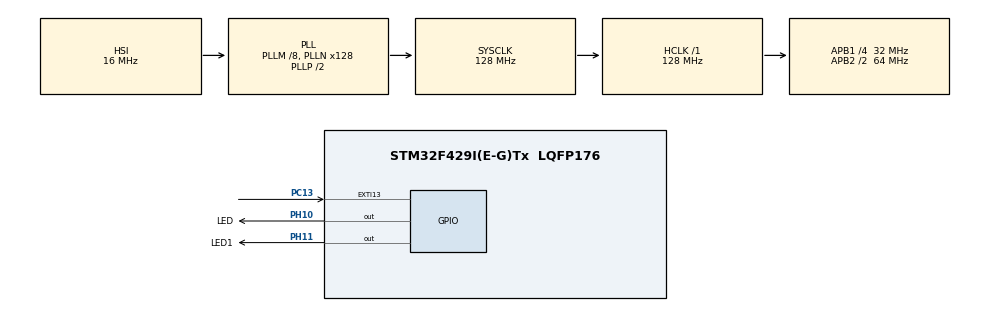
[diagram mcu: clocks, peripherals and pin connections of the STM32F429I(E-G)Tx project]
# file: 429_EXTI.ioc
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Mcu.Family=STM32F4
Mcu.Name=STM32F429I(E-G)Tx
Mcu.Package=LQFP176
NVIC.EXTI15_10_IRQn=true\:1\:0\:true\:false\:true\:true\:true
NVIC.PriorityGroup=NVIC_PRIORITYGROUP_4
PA13.Mode=Serial_Wire
PA13.Signal=SYS_JTMS-SWDIO
PA14.Mode=Serial_Wire
PA14.Signal=SYS_JTCK-SWCLK
PC13.GPIO_ModeDefaultEXTI=GPIO_MODE_IT_RISING_FALLING
PC13.GPIO_PuPd=GPIO_PULLUP
PC13.Signal=GPXTI13
PC14/OSC32_IN.Mode=LSE-External-Oscillator
PC14/OSC32_IN.Signal=RCC_OSC32_IN
PC15/OSC32_OUT.Mode=LSE-External-Oscillator
PC15/OSC32_OUT.Signal=RCC_OSC32_OUT
PH0/OSC_IN.Mode=HSE-External-Oscillator
PH0/OSC_IN.Signal=RCC_OSC_IN
PH1/OSC_OUT.Mode=HSE-External-Oscillator
PH1/OSC_OUT.Signal=RCC_OSC_OUT
PH10.GPIO_Label=LED
PH10.GPIO_PuPd=GPIO_NOPULL
PH10.PinState=GPIO_PIN_SET
PH10.Signal=GPIO_Output
PH11.GPIO_Label=LED1
PH11.GPIO_PuPd=GPIO_PULLUP
PH11.PinState=GPIO_PIN_SET
PH11.Signal=GPIO_Output
ProjectManager.HeapSize=0x200
ProjectManager.StackSize=0x400
ProjectManager.TargetToolchain=MDK-ARM V5
RCC.48MHZClocksFreq_Value=64000000
RCC.AHBFreq_Value=128000000
RCC.APB1CLKDivider=RCC_HCLK_DIV4
RCC.APB1Freq_Value=32000000
RCC.APB1TimFreq_Value=64000000
RCC.APB2CLKDivider=RCC_HCLK_DIV2
RCC.APB2Freq_Value=64000000
RCC.APB2TimFreq_Value=128000000
RCC.CortexFreq_Value=128000000
RCC.HCLKFreq_Value=128000000
RCC.HSE_VALUE=25000000
RCC.HSI_VALUE=16000000
RCC.PLLM=8
RCC.PLLN=128
RCC.SYSCLKFreq_VALUE=128000000
RCC.SYSCLKSource=RCC_SYSCLKSOURCE_PLLCLK
RCC.VCOOutputFreq_Value=256000000
board=custom

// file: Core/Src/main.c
/* USER CODE BEGIN Header */
/**
  ******************************************************************************
  * @file           : main.c
  * @brief          : Main program body
  ******************************************************************************
  * @attention
  *
  * <h2><center>&copy; Copyright (c) 2022 STMicroelectronics.
  * All rights reserved.</center></h2>
  *
  * This software component is licensed by ST under BSD 3-Clause license,
  * the "License"; You may not use this file except in compliance with the
  * License. You may obtain a copy of the License at:
  *                        opensource.org/licenses/BSD-3-Clause
  *
  ******************************************************************************
  */
/* USER CODE END Header */
#include "main.h"
#include "gpio.h"

void SystemClock_Config(void);

/* USER CODE BEGIN 0 */
void HAL_GPIO_EXTI_Callback(uint16_t GPIO_Pin)
{
	if(HAL_GPIO_ReadPin(GPIOC,GPIO_PIN_13)==GPIO_PIN_SET)
	{
		HAL_GPIO_WritePin(LED_GPIO_Port,LED_Pin,GPIO_PIN_RESET);
	}
	else if(HAL_GPIO_ReadPin(GPIOC,GPIO_PIN_13)==GPIO_PIN_RESET)
	{
		HAL_GPIO_WritePin(LED_GPIO_Port,LED_Pin,GPIO_PIN_SET);
	}
}
/* USER CODE END 0 */

int main(void)
{

  /* MCU Configuration--------------------------------------------------------*/

  /* Reset of all peripherals, Initializes the Flash interface and the Systick. */
  HAL_Init();

  /* Configure the system clock */
  SystemClock_Config();

  /* Initialize all configured peripherals */
  MX_GPIO_Init();

  /* Infinite loop */
  while (1)
  {

    /* USER CODE BEGIN 3 */
		HAL_GPIO_WritePin(LED1_GPIO_Port,LED1_Pin,GPIO_PIN_RESET);
		HAL_Delay(1000);
		HAL_GPIO_WritePin(LED1_GPIO_Port,LED1_Pin,GPIO_PIN_SET);
		HAL_Delay(1000);
  }
  /* USER CODE END 3 */
}

void SystemClock_Config(void)
{
  RCC_OscInitTypeDef RCC_OscInitStruct = {0};
  RCC_ClkInitTypeDef RCC_ClkInitStruct = {0};

  /** Configure the main internal regulator output voltage
  */
  __HAL_RCC_PWR_CLK_ENABLE();
  __HAL_PWR_VOLTAGESCALING_CONFIG(PWR_REGULATOR_VOLTAGE_SCALE2);
  /** Initializes the RCC Oscillators according to the specified parameters
  * in the RCC_OscInitTypeDef structure.
  */
  RCC_OscInitStruct.OscillatorType = RCC_OSCILLATORTYPE_HSI;
  RCC_OscInitStruct.HSIState = RCC_HSI_ON;
  RCC_OscInitStruct.HSICalibrationValue = RCC_HSICALIBRATION_DEFAULT;
  RCC_OscInitStruct.PLL.PLLState = RCC_PLL_ON;
  RCC_OscInitStruct.PLL.PLLSource = RCC_PLLSOURCE_HSI;
  RCC_OscInitStruct.PLL.PLLM = 8;
  RCC_OscInitStruct.PLL.PLLN = 128;
  RCC_OscInitStruct.PLL.PLLP = RCC_PLLP_DIV2;
  RCC_OscInitStruct.PLL.PLLQ = 4;
  if (HAL_RCC_OscConfig(&RCC_OscInitStruct) != HAL_OK)
  {
    Error_Handler();
  }
  /** Initializes the CPU, AHB and APB buses clocks
  */
  RCC_ClkInitStruct.ClockType = RCC_CLOCKTYPE_HCLK|RCC_CLOCKTYPE_SYSCLK
                              |RCC_CLOCKTYPE_PCLK1|RCC_CLOCKTYPE_PCLK2;
  RCC_ClkInitStruct.SYSCLKSource = RCC_SYSCLKSOURCE_PLLCLK;
  RCC_ClkInitStruct.AHBCLKDivider = RCC_SYSCLK_DIV1;
  RCC_ClkInitStruct.APB1CLKDivider = RCC_HCLK_DIV4;
  RCC_ClkInitStruct.APB2CLKDivider = RCC_HCLK_DIV2;

  if (HAL_RCC_ClockConfig(&RCC_ClkInitStruct, FLASH_LATENCY_4) != HAL_OK)
  {
    Error_Handler();
  }
}

void Error_Handler(void)
{
  __disable_irq();
  while (1)
  {
  }
}

/************************ (C) COPYRIGHT STMicroelectronics *****END OF FILE****/
